AUTOSAR XML (schema 4-2-2)
package /Components
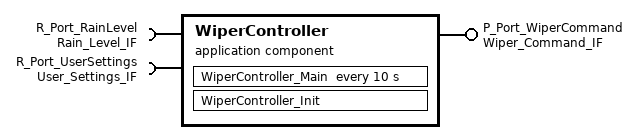
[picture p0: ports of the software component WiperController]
  application sw component type WiperController
    provide port P_Port_WiperCommand: provided-interface=Wiper_Command_IF
    require port R_Port_RainLevel: required-interface=Rain_Level_IF
    require port R_Port_UserSettings: required-interface=User_Settings_IF
    behavior WiperController_InternalBehavior
      init event WiperController_InitEvent: start-on-event=WiperController_Init
      timing event WiperController_MainEvent: start-on-event=WiperController_Main, period=10
      runnable WiperController_Init
        data-send-points:
          access VA_FrontCmd_Init: accessed-variable=P_Port_WiperCommand.front_wiper_cmd
          access VA_RearCmd_Init: accessed-variable=P_Port_WiperCommand.rear_wiper_cmd
      runnable WiperController_Main: minimum-start-interval=10
        data-receive-point-by-arguments:
          4 x access:
            VA_RainIntensity_Read: accessed-variable=R_Port_RainLevel.rain_intensity
            VA_UserMode_Read: accessed-variable=R_Port_UserSettings.wiper_mode_auto
            VA_FrontManual_Read: accessed-variable=R_Port_UserSettings.front_manual_speed
            VA_RearManual_Read: accessed-variable=R_Port_UserSettings.rear_manual_speed
        data-send-points:
          access VA_FrontCmd_Send: accessed-variable=P_Port_WiperCommand.front_wiper_cmd
          access VA_RearCmd_Send: accessed-variable=P_Port_WiperCommand.rear_wiper_cmd
